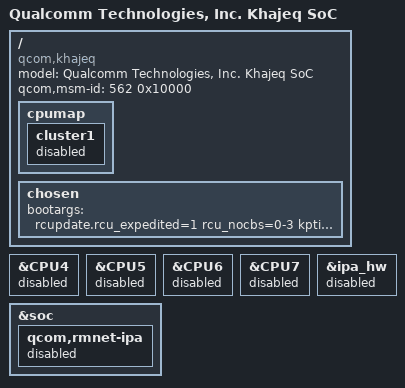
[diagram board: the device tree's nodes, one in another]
/dts-v1/;

#include "khaje.dtsi"

/ {
	model = "Qualcomm Technologies, Inc. Khajeq SoC";
	compatible = "qcom,khajeq";
	qcom,msm-id = <562 0x10000>;

	cpumap {
		cluster1 {
			status = "disabled";
		};
	};

	/delete-node/ chosen;
	chosen {
		bootargs = "rcupdate.rcu_expedited=1 rcu_nocbs=0-3 kpti=off nr_cpus=4";
	};
};

&CPU4 {
	status = "disabled";
};

&CPU5 {
	status = "disabled";
};

&CPU6 {
	status = "disabled";
};

&CPU7 {
	status = "disabled";
};

&soc {

	/delete-node/ qcom,chd_gold;

	qcom,rmnet-ipa {
		status = "disabled";
	};

};

&ipa_hw {
	status = "disabled";
};
